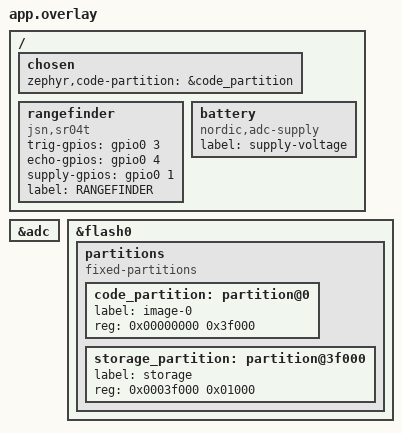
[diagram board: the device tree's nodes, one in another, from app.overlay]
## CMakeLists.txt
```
# Copyright (c) 2026 Ben Wolsieffer
# SPDX-License-Identifier: GPL-3.0-or-later

cmake_minimum_required(VERSION 3.13.1)

if(NOT ZEPHYR_TOOLCHAIN_VARIANT)
    set(ZEPHYR_TOOLCHAIN_VARIANT gnuarmemb)
endif()
if(NOT BOARD)
    set(BOARD nrf51_ble400)
endif()

find_package(Zephyr REQUIRED HINTS $ENV{ZEPHYR_BASE})
project(SensorFirmware LANGUAGES C)

add_subdirectory(src)
```

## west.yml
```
manifest:
  remotes:
    - name: zephyrproject-rtos
      url-base: https://github.com/zephyrproject-rtos
    - name: lopsided98
      url-base: https://github.com/lopsided98
  projects:
    - name: zephyr
      remote: lopsided98
      revision: 487d489b6f0abbbab754a559627222def971b493
      import:
        name-allowlist:
          - cmsis_6
          - hal_nordic
          - mbedtls
          - tf-psa-crypto
    - name: west-nix
      remote: lopsided98
      revision: fc5717a5981a9fd43939a692e8fe7c73c13a9103
      import: true
      path: tools/west-nix
  self:
    path: firmware
```

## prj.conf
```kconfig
### General
# Heap, used by TF-PSA-Crypto
CONFIG_COMMON_LIBC_MALLOC_ARENA_SIZE=512
# BLE pairing work uses 1056 bytes
CONFIG_SYSTEM_WORKQUEUE_STACK_SIZE=1280
# New ISR scheme needed for LTO
CONFIG_ISR_TABLES_LOCAL_DECLARATION=y

### Thread priorities
CONFIG_MAIN_THREAD_PRIORITY=0
# Prevent crypto tasks from blocking logging
CONFIG_LOG_PROCESS_THREAD_CUSTOM_PRIORITY=y
CONFIG_LOG_PROCESS_THREAD_PRIORITY=13
# Run slow crypto tasks in background
CONFIG_BT_LONG_WQ_PRIO=14

### BLE config
CONFIG_BT=y
CONFIG_BT_PERIPHERAL=y
CONFIG_BT_DEVICE_NAME="Water Level"
CONFIG_BT_DEVICE_APPEARANCE=5184
CONFIG_BT_MAX_CONN=2
CONFIG_BT_MAX_PAIRED=2

### BLE security
CONFIG_BT_SMP=y
CONFIG_BT_SMP_SC_ONLY=y
# Workqueue for long running crypto tasks
CONFIG_BT_LONG_WQ=y
# BLE pairing with a fixed passkey can be easily brute forced [0]. This leaves
# it with the same security as always enabled "just works" pairing, but with the
# advantage that random (non-technical) passersby can't connect. I could display
# a random passkey over UART, but this would require disassembling the sensor to
# pair with it. In this low stakes application, I care more about reliability
# (and being able to fix problems remotely) than security.
# [0] https://insinuator.net/2021/10/change-your-ble-passkey-like-you-change-your-underwear/
CONFIG_BT_FIXED_PASSKEY=y
# Given that the fixed passkey provides minimal security, there is no harm in
# disclosing it in the public repo. It is just intended to keep out curious
# passersby.
CONFIG_BT_DEFAULT_PASSKEY=207943
CONFIG_BT_SETTINGS=y

CONFIG_FLASH=y
CONFIG_FLASH_PAGE_LAYOUT=y
CONFIG_FLASH_MAP=y
CONFIG_NVS=y
CONFIG_SETTINGS=y
CONFIG_SETTINGS_NVS=y

# Logging
CONFIG_LOG=y
CONFIG_LOG_MODE_DEFERRED=y

### Water level sensor
CONFIG_GPIO=y
CONFIG_PM_DEVICE=y
CONFIG_SENSOR=y
CONFIG_JSN_SR04T=y

### Temperature sensor
CONFIG_TEMP_NRF5=y

### Battery voltage
CONFIG_ADC=y
CONFIG_NRFX_ADC_SUPPLY=y

### Crash handling
CONFIG_REBOOT=y
```

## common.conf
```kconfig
# BLE config
CONFIG_BT=y
CONFIG_BT_PERIPHERAL=y
CONFIG_BT_DEVICE_NAME="Water Level"
CONFIG_BT_DEVICE_APPEARANCE=5184
CONFIG_BT_MAX_CONN=2
CONFIG_BT_MAX_PAIRED=2

# BLE security
CONFIG_BT_SMP=y
CONFIG_BT_SMP_SC_ONLY=y
CONFIG_BT_FIXED_PASSKEY=y
CONFIG_BT_DEFAULT_PASSKEY=207943
CONFIG_BT_SETTINGS=y

CONFIG_FLASH=y
CONFIG_FLASH_PAGE_LAYOUT=y
CONFIG_FLASH_MAP=y
CONFIG_NVS=y
CONFIG_SETTINGS=y
CONFIG_SETTINGS_NVS=y

# Logging
CONFIG_LOG2_MODE_DEFERRED=y

# Water level sensor
CONFIG_GPIO=y
CONFIG_DEVICE_POWER_MANAGEMENT=y
CONFIG_SENSOR=y
CONFIG_JSN_SR04T=y

# Temperature sensor
CONFIG_TEMP_NRF5=y

# Battery voltage
CONFIG_ADC=y
CONFIG_NRFX_ADC_SUPPLY=y

# Crash handling
CONFIG_REBOOT=y

# Code size optimization
CONFIG_SPI=n
```

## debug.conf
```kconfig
# Options to enable in debug builds

# Thread info for OpenOCD RTOS awareness
CONFIG_DEBUG_THREAD_INFO=y

# CONFIG_LOG_DEFAULT_LEVEL=4

# Periodically print thread stack usage
# CONFIG_THREAD_ANALYZER=y
# CONFIG_THREAD_ANALYZER_USE_LOG=y
# CONFIG_THREAD_ANALYZER_AUTO=y
# CONFIG_THREAD_ANALYZER_AUTO_INTERVAL=5
```

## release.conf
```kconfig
# Options to enable in release builds

# Enable link-time optimization
CONFIG_LTO=y
```

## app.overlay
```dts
/ {
    chosen {
        zephyr,code-partition = &code_partition;
    };

    rangefinder: rangefinder {
        status = "okay";
        compatible = "jsn,sr04t";
        trig-gpios = <&gpio0 3 GPIO_ACTIVE_HIGH>;
        echo-gpios = <&gpio0 4 GPIO_ACTIVE_HIGH>;
        supply-gpios = <&gpio0 1 GPIO_ACTIVE_HIGH>;
        label = "RANGEFINDER";
    };

    battery: battery {
        status = "okay";
        compatible = "nordic,adc-supply";
        label = "supply-voltage";
    };
};

&adc {
    status = "okay";
};

&flash0 {
    /*
     * For more information, see:
     * https://docs.zephyrproject.org/latest/guides/dts/index.html#flash-partitions
     */
    partitions {
        compatible = "fixed-partitions";
        #address-cells = <1>;
        #size-cells = <1>;

        code_partition: partition@0 {
            label = "image-0";
            reg = <0x00000000 0x3f000>;
        };
        storage_partition: partition@3f000 {
            label = "storage";
            reg = <0x0003f000 0x01000>;
        };
    };
};
```

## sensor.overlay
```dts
/ {
    chosen {
        zephyr,code-partition = &code_partition;
    };

    rangefinder: rangefinder {
        status = "ok";
        compatible = "jsn,sr04t";
        trig-gpios = <&gpio0 3 GPIO_ACTIVE_HIGH>;
        echo-gpios = <&gpio0 4 GPIO_ACTIVE_HIGH>;
        supply-gpios = <&gpio0 1 GPIO_ACTIVE_HIGH>;
        label = "RANGEFINDER";
    };

    battery: battery {
        status = "ok";
        compatible = "nordic,adc-supply";
        label = "supply-voltage";
    };
};

&adc {
    status = "okay";
};

&flash0 {
    /*
     * For more information, see:
     * https://docs.zephyrproject.org/latest/guides/dts/index.html#flash-partitions
     */
    partitions {
        compatible = "fixed-partitions";
        #address-cells = <1>;
        #size-cells = <1>;

        code_partition: partition@0 {
            label = "image-0";
            reg = <0x00000000 0x3f000>;
        };
        storage_partition: partition@3f000 {
            label = "storage";
            reg = <0x0003f000 0x01000>;
        };
    };
};
```

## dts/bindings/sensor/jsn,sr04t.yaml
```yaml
#
# Copyright (c) 2019, Ben Wolsieffer
#
# SPDX-License-Identifier: GPL-3.0-or-later
#
---
description: |
  JSN-SR04T waterproof ultrasonic rangefinder

compatible: "jsn,sr04t"

include: [base.yaml, power.yaml]

properties:
  trig-gpios:
      type: phandle-array
      required: false
      description: Trigger pin

  echo-gpios:
      type: phandle-array
      required: false
      description: Echo pin

...
```

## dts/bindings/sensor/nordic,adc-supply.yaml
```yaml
#
# Copyright (c) 2019, Ben Wolsieffer
#
# SPDX-License-Identifier: GPL-3.0-or-later
#
---
description: |
  NRFx supply voltage sensor

compatible: "nordic,adc-supply"
  
include: [base.yaml]

...
```

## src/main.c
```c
#include <zephyr/logging/log.h>
#include <zephyr/settings/settings.h>

#include "battery.h"
#include "bluetooth.h"
#include "common.h"
#include "temperature.h"
#include "watchdog.h"
#include "water_level.h"
#include "zephyr/kernel.h"

LOG_MODULE_REGISTER(main);

#define UPDATE_PERIOD K_MINUTES(15)

K_TIMER_DEFINE(update_timer, NULL, NULL);

static void run(void) {
    int err;

    k_timer_start(&update_timer, UPDATE_PERIOD, UPDATE_PERIOD);

    for (;;) {
        IF_ERR(temperature_update()) {
            LOG_ERR("Failed to update temperature (err %d)", err);
            bluetooth_set_error(ERROR_TEMPERATURE);
        }

        if (!bluetooth_get_error(ERROR_BROWNOUT)) {
            IF_ERR(water_level_update()) {
                LOG_ERR("Failed to update temperature (err %d)", err);
                bluetooth_set_error(ERROR_WATER_LEVEL);
            }
        } else {
            LOG_WRN("Not updating water level due to brownout");
        }

        IF_ERR(battery_update()) {
            LOG_ERR("Failed to update battery (err %d)", err);
            bluetooth_set_error(ERROR_BATTERY);
        }

        bluetooth_set_status(STATUS_NEW_DATA, true);

        k_timer_status_sync(&update_timer);
    }
}

void main(void) {
    int err;

    IF_ERR(watchdog_init()) { LOG_ERR("Watchdog initialization failed (err %d)", err); }

    IF_ERR(settings_subsys_init()) { LOG_ERR("Settings initialization failed (err %d)", err); }

    IF_ERR(battery_init()) { LOG_ERR("Battery initialization failed (err %d)", err); }
    IF_ERR(temperature_init()) { LOG_ERR("Temperature initialization failed (err %d)", err); }
    IF_ERR(water_level_init()) { LOG_ERR("Water level initialization failed (err %d)", err); }
    IF_ERR(bluetooth_init()) { LOG_ERR("Bluetooth initiallization failed (err %d)", err); }

    run();
}
```

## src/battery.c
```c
#include "battery.h"

#include <zephyr/drivers/adc.h>
#include <zephyr/drivers/sensor.h>
#include <zephyr/logging/log.h>
#include <zephyr/sys/atomic.h>

#include "common.h"

LOG_MODULE_REGISTER(battery);

static const uint16_t BATTERY_FULL_MILLIVOLTS = 3200;
static const uint16_t BATTERY_EMPTY_MILLIVOLTS = 1800;

static struct {
    const struct device* const battery;
    atomic_t level;    // %
    atomic_t voltage;  // mV
} state = {
    .battery = DEVICE_DT_GET(DT_NODELABEL(battery)),
    .level = ATOMIC_INIT(0),
    .voltage = ATOMIC_INIT(0),
};

int battery_init(void) {
    if (!device_is_ready(state.battery)) {
        LOG_ERR_DEVICE_NOT_READY(state.battery);
        return -ENODEV;
    }

    return 0;
}

int battery_update(void) {
    int err;
    RET_ERR(sensor_sample_fetch(state.battery));

    struct sensor_value voltage_value;
    RET_ERR(sensor_channel_get(state.battery, SENSOR_CHAN_VOLTAGE, &voltage_value));

    uint32_t voltage = voltage_value.val1 * 1000 + voltage_value.val2 / 1000;
    voltage = MIN(voltage, UINT16_MAX);
    atomic_set(&state.voltage, voltage);

    uint32_t level = (voltage - BATTERY_EMPTY_MILLIVOLTS) * 100 /
                     (BATTERY_FULL_MILLIVOLTS - BATTERY_EMPTY_MILLIVOLTS);
    level = MIN(level, 100);
    atomic_set(&state.level, level);

    LOG_DBG("Battery state: %d%%, %d.%d V", level, voltage_value.val1, voltage_value.val2);

    return 0;
}

uint8_t battery_get_level(void) { return (uint8_t)atomic_get(&state.level); }

uint16_t battery_get_voltage(void) { return (uint16_t)atomic_get(&state.voltage); }
```

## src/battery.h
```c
#pragma once

#include <stdint.h>

int battery_init(void);

int battery_update(void);

/**
 * Get the battery level as a percentage.
 *
 * @return percent of the battery remaining (0-100)
 */
uint8_t battery_get_level(void);

/**
 * Get the battery voltage in millivolts.
 *
 * @return voltage in millivolts
 */
uint16_t battery_get_voltage(void);
```

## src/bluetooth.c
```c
#include "bluetooth.h"

#include <errno.h>
#include <zephyr/bluetooth/bluetooth.h>
#include <zephyr/bluetooth/conn.h>
#include <zephyr/bluetooth/gatt.h>
#include <zephyr/bluetooth/hci.h>
#include <zephyr/bluetooth/uuid.h>
#include <zephyr/logging/log.h>
#include <zephyr/settings/settings.h>

#include "battery.h"
#include "common.h"
#include "temperature.h"
#include "water_level.h"

LOG_MODULE_REGISTER(bluetooth);

#define BT_CPF_FORMAT_UINT16 0x6

// Water Level Service (WLS)
#define BT_UUID_WLS_VAL \
    0x01, 0xc7, 0xe3, 0x00, 0xfa, 0xaf, 0x11, 0xe8, 0x8b, 0xe5, 0x07, 0x9b, 0x30, 0x95, 0xdd, 0x67

// System Control Service (SCS)
#define BT_UUID_SCS_VAL \
    0xa1, 0xf8, 0x20, 0x0f, 0xa2, 0xc0, 0x4e, 0x72, 0x8e, 0x88, 0x61, 0x96, 0xcb, 0xdf, 0xef, 0x89

static atomic_t error = ATOMIC_INIT(0);

static uint8_t status_sd_data[] = {BT_UUID_SCS_VAL, 0x00, 0x00, 0x00, 0x00};
static uint32_t* status = (uint32_t*)&status_sd_data[16];

static void bluetooth_ready(int err);

static ssize_t bluetooth_battery_read(struct bt_conn* conn, const struct bt_gatt_attr* attr,
                                      void* buf, uint16_t len, uint16_t offset);

static ssize_t bluetooth_temperature_read(struct bt_conn* conn, const struct bt_gatt_attr* attr,
                                          void* buf, uint16_t len, uint16_t offset);

static ssize_t bluetooth_water_level_read(struct bt_conn* conn, const struct bt_gatt_attr* attr,
                                          void* buf, uint16_t len, uint16_t offset);

static ssize_t bluetooth_water_distance_read(struct bt_conn* conn, const struct bt_gatt_attr* attr,
                                             void* buf, uint16_t len, uint16_t offset);

static ssize_t bluetooth_tank_depth_read(struct bt_conn* conn, const struct bt_gatt_attr* attr,
                                         void* buf, uint16_t len, uint16_t offset);

static ssize_t bluetooth_tank_depth_write(struct bt_conn* conn, const struct bt_gatt_attr* attr,
                                          const void* buf, uint16_t len, uint16_t offset,
                                          uint8_t flags);

static ssize_t bluetooth_error_read(struct bt_conn* conn, const struct bt_gatt_attr* attr,
                                    void* buf, uint16_t len, uint16_t offset);

static ssize_t bluetooth_error_write(struct bt_conn* conn, const struct bt_gatt_attr* attr,
                                     const void* buf, uint16_t len, uint16_t offset, uint8_t flags);

static ssize_t bluetooth_status_read(struct bt_conn* conn, const struct bt_gatt_attr* attr,
                                     void* buf, uint16_t len, uint16_t offset);

static ssize_t bluetooth_status_write(struct bt_conn* conn, const struct bt_gatt_attr* attr,
                                      const void* buf, uint16_t len, uint16_t offset,
                                      uint8_t flags);

static ssize_t bluetooth_battery_voltage_read(struct bt_conn* conn, const struct bt_gatt_attr* attr,
                                              void* buf, uint16_t len, uint16_t offset);

static const struct bt_data ad[] = {
    BT_DATA_BYTES(BT_DATA_FLAGS, (BT_LE_AD_GENERAL | BT_LE_AD_NO_BREDR)),
    BT_DATA(BT_DATA_SVC_DATA128, status_sd_data, sizeof(status_sd_data))};

static const struct bt_data sd[] = {
    BT_DATA_BYTES(BT_DATA_UUID16_ALL, BT_UUID_16_ENCODE(BT_UUID_BAS_VAL),  // Battery Service
                  BT_UUID_16_ENCODE(BT_UUID_ESS_VAL)  // Environmental Sensing Service
                  ),
    BT_DATA(BT_DATA_NAME_COMPLETE, CONFIG_BT_DEVICE_NAME, sizeof(CONFIG_BT_DEVICE_NAME) - 1),
};

// Battery Service
BT_GATT_SERVICE_DEFINE(bas_service, BT_GATT_PRIMARY_SERVICE(BT_UUID_BAS),
                       BT_GATT_CHARACTERISTIC(BT_UUID_BAS_BATTERY_LEVEL, BT_GATT_CHRC_READ,
                                              BT_GATT_PERM_READ_AUTHEN, bluetooth_battery_read,
                                              NULL, NULL), );

// Environmental Sensing Service
BT_GATT_SERVICE_DEFINE(ess_service, BT_GATT_PRIMARY_SERVICE(BT_UUID_ESS),
                       BT_GATT_CHARACTERISTIC(BT_UUID_TEMPERATURE, BT_GATT_CHRC_READ,
                                              BT_GATT_PERM_READ_AUTHEN, bluetooth_temperature_read,
                                              NULL, NULL), );

// Water Level Service
static struct bt_uuid_128 bt_uuid_wls = BT_UUID_INIT_128(BT_UUID_WLS_VAL);

static struct bt_uuid_128 bt_uuid_wls_water_level = BT_UUID_INIT_128(
    0x24, 0x4c, 0xbc, 0x99, 0x57, 0x6d, 0x4e, 0x4a, 0xb5, 0xa1, 0x9a, 0x72, 0xa5, 0xe6, 0xf2, 0x7a);

static struct bt_uuid_128 bt_uuid_wls_water_distance = BT_UUID_INIT_128(
    0x01, 0x31, 0x2d, 0x06, 0x4f, 0xa7, 0x42, 0x94, 0x82, 0x3b, 0x84, 0x47, 0x54, 0x55, 0x47, 0xfe);

static struct bt_uuid_128 bt_uuid_wls_tank_depth = BT_UUID_INIT_128(
    0xd3, 0xc6, 0xec, 0xcb, 0x2f, 0x4a, 0x49, 0x8c, 0xbf, 0xde, 0x5c, 0x76, 0x3d, 0xee, 0x57, 0xd3);

static const struct bt_gatt_cpf wls_water_level_cpf = {.format = BT_CPF_FORMAT_UINT16,
                                                       .exponent = -3};

BT_GATT_SERVICE_DEFINE(
    wls_service, BT_GATT_PRIMARY_SERVICE(&bt_uuid_wls),
    BT_GATT_CHARACTERISTIC(&bt_uuid_wls_water_level.uuid, BT_GATT_CHRC_READ,
                           BT_GATT_PERM_READ_AUTHEN, bluetooth_water_level_read, NULL, NULL),
    BT_GATT_CPF(&wls_water_level_cpf),
    BT_GATT_CHARACTERISTIC(&bt_uuid_wls_water_distance.uuid, BT_GATT_CHRC_READ,
                           BT_GATT_PERM_READ_AUTHEN, bluetooth_water_distance_read, NULL, NULL),
    BT_GATT_CPF(&wls_water_level_cpf),
    BT_GATT_CHARACTERISTIC(&bt_uuid_wls_tank_depth.uuid, BT_GATT_CHRC_READ | BT_GATT_CHRC_WRITE,
                           BT_GATT_PERM_READ_AUTHEN | BT_GATT_PERM_WRITE_AUTHEN,
                           bluetooth_tank_depth_read, bluetooth_tank_depth_write, NULL),
    BT_GATT_CPF(&wls_water_level_cpf), );

static struct bt_uuid_128 bt_uuid_scs = BT_UUID_INIT_128(BT_UUID_SCS_VAL);

static struct bt_uuid_128 bt_uuid_scs_error = BT_UUID_INIT_128(
    0xe3, 0xf1, 0x14, 0x77, 0xc3, 0xcb, 0x4a, 0xa7, 0xbd, 0xc6, 0x7b, 0x84, 0x83, 0x2f, 0x5f, 0xc2);

static struct bt_uuid_128 bt_uuid_scs_status = BT_UUID_INIT_128(
    0x5b, 0x32, 0xf5, 0x09, 0xf9, 0x61, 0x4b, 0x28, 0x95, 0xc1, 0xd4, 0xed, 0xae, 0x5d, 0xc1, 0x57);

static struct bt_uuid_128 bt_uuid_scs_battery_voltage = BT_UUID_INIT_128(
    0x21, 0xc1, 0x38, 0x8b, 0x44, 0x90, 0x40, 0x26, 0x83, 0x7c, 0x05, 0xad, 0x6b, 0x55, 0x08, 0xdd);

static const struct bt_gatt_cpf scs_battery_voltage_cpf = {.format = BT_CPF_FORMAT_UINT16,
                                                           .exponent = -3};

BT_GATT_SERVICE_DEFINE(
    scs_service, BT_GATT_PRIMARY_SERVICE(&bt_uuid_scs),
    BT_GATT_CHARACTERISTIC(&bt_uuid_scs_error.uuid, BT_GATT_CHRC_READ | BT_GATT_CHRC_WRITE,
                           BT_GATT_PERM_READ_AUTHEN | BT_GATT_PERM_WRITE_AUTHEN,
                           bluetooth_error_read, bluetooth_error_write, NULL),
    BT_GATT_CHARACTERISTIC(&bt_uuid_scs_status.uuid, BT_GATT_CHRC_READ | BT_GATT_CHRC_WRITE,
                           BT_GATT_PERM_READ_AUTHEN | BT_GATT_PERM_WRITE_AUTHEN,
                           bluetooth_status_read, bluetooth_status_write, NULL),
    BT_GATT_CHARACTERISTIC(&bt_uuid_scs_battery_voltage.uuid, BT_GATT_CHRC_READ,
                           BT_GATT_PERM_READ_AUTHEN, bluetooth_battery_voltage_read, NULL, NULL),
    BT_GATT_CPF(&scs_battery_voltage_cpf), );

static void bluetooth_conn_count_callback(struct bt_conn* conn, void* data) {
    struct bt_conn_info info;
    bt_conn_get_info(conn, &info);
    if (info.role == BT_CONN_ROLE_PERIPHERAL) {
        ++*((size_t*)data);
    }
}

static size_t bluetooth_get_conn_count() {
    size_t count = 0;
    bt_conn_foreach(BT_CONN_TYPE_ALL, bluetooth_conn_count_callback, &count);
    return count;
}

static int bluetooth_advertising_start() {
    LOG_DBG("Starting advertising...");
    return bt_le_adv_start(BT_LE_ADV_PARAM(BT_LE_ADV_OPT_CONN,
                                           BT_GAP_ADV_SLOW_INT_MIN,
                                           BT_GAP_ADV_SLOW_INT_MAX,
                                           NULL  // undirected advertising
                                           ),
                           ad,
                           ARRAY_SIZE(ad),
                           sd,
                           ARRAY_SIZE(sd));
}

static void bluetooth_connected(struct bt_conn* conn, uint8_t err) {
    char addr[BT_ADDR_LE_STR_LEN];
    bt_addr_le_to_str(bt_conn_get_dst(conn), addr, sizeof(addr));

    if (err) {
        LOG_ERR("Failed to connect to: %s (err %d)", addr, err);
        return;
    }

    LOG_DBG("Connected to: %s", addr);

    //    IF_ERR(bt_conn_security(conn, BT_SECURITY_FIPS)) {
    //        LOG_ERR("Failed to enable security (err %d)", err);
    //        bt_conn_disconnect(conn, BT_HCI_ERR_INSUFFICIENT_SECURITY);
    //    }
}

static void bluetooth_disconnected(struct bt_conn* conn, uint8_t reason) {
    char addr[BT_ADDR_LE_STR_LEN];
    bt_addr_le_to_str(bt_conn_get_dst(conn), addr, sizeof(addr));

    LOG_DBG("Disconnected from: %s", addr);

    // Stop advertising if no one else is connected and the data has been retrieved
    // We check for a single connection because the connection that triggered this callback is still
    // included in the list.
    if (!(*status & STATUS_NEW_DATA)) {
        size_t conn_count = bluetooth_get_conn_count();
        if (conn_count <= 1) {
            int err = bt_le_adv_stop();
            if (err < 0) {
                LOG_ERR("Failed to stop advertising (err %d)", err);
            } else {
                LOG_DBG("Stopped advertising at disconnect");
            }
        } else {
            LOG_DBG("%zu clients still connected, not stopping advertising", conn_count - 1);
        }
    }
}

static struct bt_conn_cb conn_callbacks = {.connected = bluetooth_connected,
                                           .disconnected = bluetooth_disconnected};

static void bluetooth_passkey_display(struct bt_conn* conn, unsigned int passkey) {
    LOG_INF("Passkey: %d", passkey);
}

static void bluetooth_auth_cancel(struct bt_conn* conn) {
    char addr[BT_ADDR_LE_STR_LEN];
    bt_addr_le_to_str(bt_conn_get_dst(conn), addr, sizeof(addr));

    LOG_WRN("Authentication failed with: %s", addr);
}

static void bluetooth_pairing_complete(struct bt_conn* conn, bool bonded) {
    char addr[BT_ADDR_LE_STR_LEN];
    bt_addr_le_to_str(bt_conn_get_dst(conn), addr, sizeof(addr));

    LOG_DBG("Paired with: %s", addr);
}

static void bluetooth_pairing_failed(struct bt_conn* conn, enum bt_security_err reason) {
    char addr[BT_ADDR_LE_STR_LEN];
    bt_addr_le_to_str(bt_conn_get_dst(conn), addr, sizeof(addr));

    LOG_WRN("Pairing failed with %s with error: %d", addr, reason);
}

static struct bt_conn_auth_cb auth_callbacks = {
    .passkey_display = bluetooth_passkey_display,
    .passkey_entry = NULL,
    .passkey_confirm = NULL,
    .cancel = bluetooth_auth_cancel,
};

static struct bt_conn_auth_info_cb auth_info_callbacks = {
    .pairing_complete = bluetooth_pairing_complete,
    .pairing_failed = bluetooth_pairing_failed,
};

static void bluetooth_ready(int err) {
    if (err) {
        LOG_ERR("Initialization failed (err %d)", err);
        return;
    }

    IF_ERR(settings_load()) { LOG_ERR("Loading settings failed (err %d)", err); }

    IF_ERR(bt_passkey_set(CONFIG_BT_DEFAULT_PASSKEY)) {
        LOG_ERR("Setting passkey failed (err %d)", err);
        // This would be a security issue
        return;
    }

    bt_conn_cb_register(&conn_callbacks);
    bt_conn_auth_cb_register(&auth_callbacks);
    bt_conn_auth_info_cb_register(&auth_info_callbacks);
}

static ssize_t bluetooth_battery_read(struct bt_conn* conn, const struct bt_gatt_attr* attr,
                                      void* buf, uint16_t len, uint16_t offset) {
    const uint8_t level = battery_get_level();
    return bt_gatt_attr_read(conn, attr, buf, len, offset, &level, sizeof(level));
}

static ssize_t bluetooth_temperature_read(struct bt_conn* conn, const struct bt_gatt_attr* attr,
                                          void* buf, uint16_t len, uint16_t offset) {
    const int16_t temperature = temperature_get();
    return bt_gatt_attr_read(conn, attr, buf, len, offset, &temperature, sizeof(temperature));
}

static ssize_t bluetooth_water_level_read(struct bt_conn* conn, const struct bt_gatt_attr* attr,
                                          void* buf, uint16_t len, uint16_t offset) {
    const uint16_t water_level = water_level_get();
    return bt_gatt_attr_read(conn, attr, buf, len, offset, &water_level, sizeof(water_level));
}

static ssize_t bluetooth_water_distance_read(struct bt_conn* conn, const struct bt_gatt_attr* attr,
                                             void* buf, uint16_t len, uint16_t offset) {
    const uint16_t water_distance = water_level_get_water_distance();
    return bt_gatt_attr_read(conn, attr, buf, len, offset, &water_distance, sizeof(water_distance));
}

static ssize_t bluetooth_tank_depth_read(struct bt_conn* conn, const struct bt_gatt_attr* attr,
                                         void* buf, uint16_t len, uint16_t offset) {
    const uint16_t tank_depth = water_level_get_tank_depth();
    return bt_gatt_attr_read(conn, attr, buf, len, offset, &tank_depth, sizeof(tank_depth));
}

static ssize_t bluetooth_tank_depth_write(struct bt_conn* conn, const struct bt_gatt_attr* attr,
                                          const void* buf, uint16_t len, uint16_t offset,
                                          uint8_t flags) {
    uint16_t tank_depth = 0;

    if (offset + len > sizeof(tank_depth)) {
        return BT_GATT_ERR(BT_ATT_ERR_INVALID_OFFSET);
    }

    memcpy(((uint8_t*)&tank_depth) + offset, buf, len);
    water_level_set_tank_depth(tank_depth);

    return len;
}

static ssize_t bluetooth_error_read(struct bt_conn* conn, const struct bt_gatt_attr* attr,
                                    void* buf, uint16_t len, uint16_t offset) {
    return bt_gatt_attr_read(conn, attr, buf, len, offset, &error, sizeof(error));
}

static ssize_t bluetooth_error_write(struct bt_conn* conn, const struct bt_gatt_attr* attr,
                                     const void* buf, uint16_t len, uint16_t offset,
                                     uint8_t flags) {
    if (offset + len > sizeof(error)) {
        return BT_GATT_ERR(BT_ATT_ERR_INVALID_OFFSET);
    }

    uint32_t error_write = 0;
    uint32_t mask_write = 0;
    memcpy(((uint8_t*)&error_write) + offset, buf, len);
    memset(((uint8_t*)&mask_write) + offset, 0xff, len);

    // Don't let the user set error bits, only clear
    atomic_and(&error, ~mask_write | error_write);

    return len;
}

static void bluetooth_status_update() {
    // Update the advertising and service data
    bt_le_adv_update_data(ad, ARRAY_SIZE(ad), sd, ARRAY_SIZE(sd));

    if (*status & STATUS_NEW_DATA) {
        // If there is new data, start advertising
        int err;
        IF_ERR(bluetooth_advertising_start()) {
            if (err == -EALREADY) {
                LOG_DBG("Advertising already started");
            } else {
                LOG_ERR("Advertising failed to restart (err %d)", err);
            }
        }
    } else if (bluetooth_get_conn_count() == 0) {
        // If there is no longer new data and no one is connected, stop advertising
        bt_le_adv_stop();
        LOG_DBG("Stopped advertising, no clients connected");
    }
}

static ssize_t bluetooth_status_read(struct bt_conn* conn, const struct bt_gatt_attr* attr,
                                     void* buf, uint16_t len, uint16_t offset) {
    return bt_gatt_attr_read(conn, attr, buf, len, offset, status, sizeof(*status));
}

static ssize_t bluetooth_status_write(struct bt_conn* conn, const struct bt_gatt_attr* attr,
                                      const void* buf, uint16_t len, uint16_t offset,
                                      uint8_t flags) {
    if (offset + len > sizeof(*status)) {
        return BT_GATT_ERR(BT_ATT_ERR_INVALID_OFFSET);
    }

    uint32_t status_write = 0;
    uint32_t mask_write = 0;
    memcpy(((uint8_t*)&status_write) + offset, buf, len);
    memset(((uint8_t*)&mask_write) + offset, 0xff, len);

    // Only set bits specified by the write mask
    // FIXME: this is cheating because we don't use atomic operations. It
    //  should be fine though because this function is called from a
    //  cooperative thread.
    *status = (*status & ~mask_write) | status_write;

    bluetooth_status_update();

    return len;
}

static ssize_t bluetooth_battery_voltage_read(struct bt_conn* conn, const struct bt_gatt_attr* attr,
                                              void* buf, uint16_t len, uint16_t offset) {
    const uint16_t voltage = battery_get_voltage();
    return bt_gatt_attr_read(conn, attr, buf, len, offset, &voltage, sizeof(voltage));
}

int bluetooth_init(void) { return bt_enable(bluetooth_ready); }

void bluetooth_set_error(enum system_error e) { atomic_or(&error, e); }

bool bluetooth_get_error(enum system_error e) { return atomic_get(&error) & e; }

void bluetooth_set_status(enum system_status s, bool value) {
    if (value) {
        *status |= s;
    } else {
        *status &= ~s;
    }

    bluetooth_status_update();
}
```

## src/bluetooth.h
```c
#pragma once

#include <stdbool.h>
#include <zephyr/sys/util.h>

enum system_error {
    ERROR_TEMPERATURE = BIT(0),
    ERROR_BATTERY = BIT(1),
    ERROR_WATER_LEVEL = BIT(2),
    ERROR_BROWNOUT = BIT(3),
    ERROR_CRASH = BIT(4),
};

enum system_status {
    STATUS_NEW_DATA = BIT(0),
};

int bluetooth_init(void);

/**
 * Set a latched error bit.
 *
 * @param e error bit to set
 */
void bluetooth_set_error(enum system_error e);

/**
 * Check whether an error bit is set.
 *
 * @param e error bit to get
 */
bool bluetooth_get_error(enum system_error e);

/**
 * Set the value of a status bit.
 * @param s status bit to set
 * @param value value of the bit
 */
void bluetooth_set_status(enum system_status s, bool value);
```

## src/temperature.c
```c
#include "temperature.h"

#include <zephyr/device.h>
#include <zephyr/drivers/sensor.h>
#include <zephyr/logging/log.h>
#include <zephyr/settings/settings.h>
#include <zephyr/sys/atomic.h>

#include "common.h"

LOG_MODULE_REGISTER(temperature);

static struct {
    const struct device* const sensor;
    atomic_t temperature;
} state = {
    .sensor = DEVICE_DT_GET(DT_NODELABEL(temp)),
    .temperature = ATOMIC_INIT(0),
};

int temperature_init(void) {
    if (!device_is_ready(state.sensor)) {
        LOG_ERR_DEVICE_NOT_READY(state.sensor);
        return -ENODEV;
    }

    return 0;
}

int temperature_update(void) {
    int err;

    RET_ERR(sensor_sample_fetch(state.sensor));

    struct sensor_value temperature_value;

    RET_ERR(sensor_channel_get(state.sensor, SENSOR_CHAN_DIE_TEMP, &temperature_value));
    // Convert to millicelsius
    int32_t temperature = temperature_value.val1 * 100 + temperature_value.val2 / 10000;
    // Bound to 16-bit (more than enough)
    temperature = clamp(temperature, INT16_MIN, INT16_MAX);
    atomic_set(&state.temperature, temperature);

    return err;
}

uint16_t temperature_get(void) { return (uint16_t)atomic_get(&state.temperature); }
```

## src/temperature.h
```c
#pragma once

#include <stdint.h>

int temperature_init(void);

int temperature_update(void);

/**
 * Get the temperature in millicelsius.
 *
 * @return temperature in mC
 */
uint16_t temperature_get(void);
```

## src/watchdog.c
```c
#include "watchdog.h"

#include <hal/nrf_power.h>
#include <zephyr/logging/log.h>
#include <zephyr/logging/log_ctrl.h>
#include <zephyr/sys/reboot.h>

#include "bluetooth.h"

LOG_MODULE_REGISTER(watchdog);

int watchdog_init(void) {
    uint32_t reset_reason = nrf_power_resetreas_get(NRF_POWER);
    nrf_power_resetreas_clear(NRF_POWER, 0xFFFFFFFF);

    if (reset_reason & (NRF_POWER_RESETREAS_SREQ_MASK | NRF_POWER_RESETREAS_LOCKUP_MASK)) {
        bluetooth_set_error(ERROR_CRASH);
    }

    return 0;
}

FUNC_NORETURN void k_sys_fatal_error_handler(unsigned int reason, const struct arch_esf* esf) {
    LOG_ERR("FATAL ERROR... Resetting");
    LOG_PANIC();
    sys_reboot(SYS_REBOOT_COLD);
    CODE_UNREACHABLE;
}
```

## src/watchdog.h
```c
#pragma once

int watchdog_init(void);
```

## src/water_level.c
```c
#include "water_level.h"

#include <stdint.h>
#include <zephyr/device.h>
#include <zephyr/drivers/sensor.h>
#include <zephyr/logging/log.h>
#include <zephyr/pm/device.h>
#include <zephyr/pm/device_runtime.h>
#include <zephyr/settings/settings.h>

#include "bluetooth.h"
#include "common.h"
#include "zephyr/sys/util.h"

LOG_MODULE_REGISTER(water_level);

#define NUM_WATER_SAMPLES 10
#define MAX_WATER_SAMPLE_ATTEMPTS 30

static struct {
    const struct device* const rangefinder;
    atomic_t water_level;     // mm
    atomic_t water_distance;  // mm
    atomic_t tank_depth;      // mm
} state = {
    .rangefinder = DEVICE_DT_GET(DT_NODELABEL(rangefinder)),
    .water_level = ATOMIC_INIT(0),
    .water_distance = ATOMIC_INIT(0),
    .tank_depth = ATOMIC_INIT(2000),
};

static int water_level_settings_set(const char* key, size_t len_rd, settings_read_cb read_cb,
                                    void* cb_arg) {
    int err;
    int len = settings_name_next(key, NULL);
    if (!strncmp(key, "td", len)) {
        uint16_t tank_depth;
        RET_ERR(read_cb(cb_arg, &tank_depth, sizeof(tank_depth)));
        atomic_set(&state.tank_depth, tank_depth);
    } else {
        return -ENOENT;
    }
    return 0;
}

SETTINGS_STATIC_HANDLER_DEFINE(water_level_settings, "wl", NULL, water_level_settings_set, NULL,
                               NULL);

int water_level_init(void) {
    if (!device_is_ready(state.rangefinder)) {
        LOG_ERR_DEVICE_NOT_READY(state.rangefinder);
        return -ENODEV;
    }

    return 0;
}

int compare_uint32(const void* a, const void* b) {
    uint32_t val_a = *(const uint32_t*)a;
    uint32_t val_b = *(const uint32_t*)b;

    if (val_a < val_b) return -1;
    if (val_a > val_b) return 1;
    return 0;
}

int water_level_update(void) {
    int err;
    const uint32_t tank_depth = atomic_get(&state.tank_depth);
    // 6 samples >1.3x tank depth
    const uint32_t max_distance_mm = tank_depth + DIV_ROUND_CLOSEST(tank_depth, 3);

    pm_device_runtime_get(state.rangefinder);

    uint32_t distance_mm_samples[NUM_WATER_SAMPLES];

    size_t samples = 0;
    for (size_t tries = 0; tries < MAX_WATER_SAMPLE_ATTEMPTS && samples < NUM_WATER_SAMPLES;
         ++tries) {
        err = sensor_sample_fetch(state.rangefinder);
        if (!err) {
            struct sensor_value distance;
            sensor_channel_get(state.rangefinder, SENSOR_CHAN_DISTANCE, &distance);

            uint32_t distance_mm = (uint32_t)(distance.val1 * 1000 + distance.val2 / 1000);
            // Only include reasonable distance samples
            if (distance_mm < max_distance_mm) {
                distance_mm_samples[samples] = distance_mm;
                ++samples;
                LOG_DBG("Distance (sample %d): %u mm", samples, distance_mm);
            } else {
                LOG_WRN("Distance out of range: %u mm", distance_mm);
            }
        } else {
            LOG_WRN("Failed to read rangefinder (err %d)", err);
        }
        // Wait long enough between samples to allow echoes to decay
        k_sleep(K_MSEC(50));
    }

    pm_device_runtime_put(state.rangefinder);

    if (0 == samples) {
        // No samples collected, don't update distance
        LOG_ERR("No valid water level samples");
        bluetooth_set_error(ERROR_WATER_LEVEL);
        return 0;
    }

    if (samples != NUM_WATER_SAMPLES) {
        LOG_WRN("Only measured %d water level samples", samples);
        bluetooth_set_error(ERROR_WATER_LEVEL);
    }

    // Median filter
    qsort(distance_mm_samples, samples, sizeof(*distance_mm_samples), compare_uint32);
    uint32_t distance_mm_filtered;
    if (samples % 2 == 0) {
        // Even number of samples, everage middle two
        distance_mm_filtered = DIV_ROUND_CLOSEST(
            distance_mm_samples[samples / 2] + distance_mm_samples[samples / 2 - 1],
            2);
    } else {
        // Odd number of samples, single median value
        distance_mm_filtered = distance_mm_samples[samples / 2];
    }

    LOG_INF("Distance (median): %u mm", distance_mm_filtered);

    atomic_set(&state.water_distance, distance_mm_filtered);
    atomic_set(&state.water_level,
               tank_depth > distance_mm_filtered ? tank_depth - distance_mm_filtered : 0);

    return 0;
}

uint16_t water_level_get(void) { return (uint16_t)atomic_get(&state.water_level); }

uint16_t water_level_get_water_distance(void) {
    return (uint16_t)atomic_get(&state.water_distance);
}

uint16_t water_level_get_tank_depth(void) { return (uint16_t)atomic_get(&state.tank_depth); }

void water_level_set_tank_depth(uint16_t depth) {
    atomic_set(&state.tank_depth, depth);
    settings_save_one("wl/td", &depth, sizeof(depth));
}
```

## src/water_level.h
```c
#pragma once

#include <stdint.h>

int water_level_init(void);

int water_level_update(void);

uint16_t water_level_get(void);

uint16_t water_level_get_water_distance(void);

uint16_t water_level_get_tank_depth(void);

/**
 * Set the depth of the water tank.
 *
 * @param depth depth in millimeters
 */
void water_level_set_tank_depth(uint16_t depth);
```
